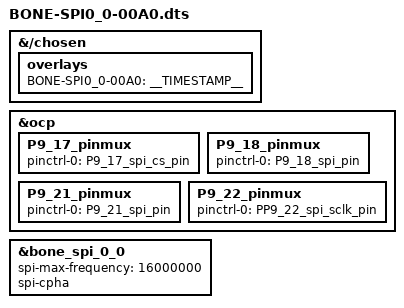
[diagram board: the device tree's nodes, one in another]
/*
 * Copyright (C) 2020 Deepak Khatri <deepaklorkhatri7@gmail.com>
 *
 * Virtual cape for /dev/bone/spi/0.0
 *
 * This program is free software; you can redistribute it and/or modify
 * it under the terms of the GNU General Public License version 2 as
 * published by the Free Software Foundation.
 */
 
/dts-v1/;
/plugin/;

/*
* Helper to show loaded overlays under: /proc/device-tree/chosen/overlays/
*/
&{/chosen} {
    overlays {
        BONE-SPI0_0-00A0 = __TIMESTAMP__;
    };
};

/*
* Free up the pins used by the cape from the pinmux helpers.
*/
&ocp {
    P9_17_pinmux { pinctrl-0 = <&P9_17_spi_cs_pin>; }; /* CS*/
    P9_18_pinmux { pinctrl-0 = <&P9_18_spi_pin>; }; /* MOSI */
    P9_21_pinmux { pinctrl-0 = <&P9_21_spi_pin>; }; /* MISO */
    P9_22_pinmux { pinctrl-0 = <&PP9_22_spi_sclk_pin>; }; /* CLK */
};

&bone_spi_0_0 {
    // See these files for the definition
    // https://github.com/beagleboard/BeagleBoard-DeviceTrees/src/arm/bbai-bone-buses.dtsi
    // https://github.com/beagleboard/BeagleBoard-DeviceTrees/src/arm/bbb-bone-buses.dtsi
    status = "okay";
    spi-max-frequency = <16000000>;
	spi-cpha;
};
